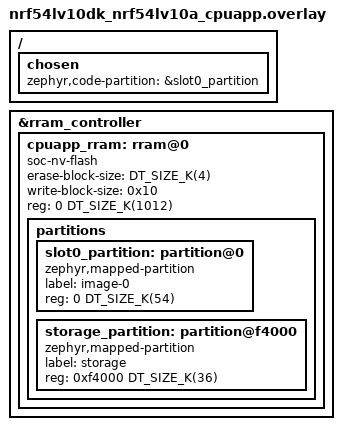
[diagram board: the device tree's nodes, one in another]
/ {
	chosen {
		zephyr,code-partition = &slot0_partition;
	};
};

/delete-node/ &cpuapp_rram;

&rram_controller {
	cpuapp_rram: rram@0 {
		compatible = "soc-nv-flash";
		erase-block-size = <DT_SIZE_K(4)>;
		write-block-size = <0x10>;
		reg = <0 DT_SIZE_K(1012)>;

		partitions {
			ranges;
			#address-cells = <1>;
			#size-cells = <1>;

			slot0_partition: partition@0 {
				compatible = "zephyr,mapped-partition";
				label = "image-0";
				reg = <0 DT_SIZE_K(54)>;
			};

			storage_partition: partition@f4000 {
				compatible = "zephyr,mapped-partition";
				label = "storage";
				reg = <0xf4000 DT_SIZE_K(36)>;
			};
		};
	};
};
